# MMC register map
Vendor: Texas Instruments
Peripheral module from a debugger description file (folder am335x).
Registers are 32-bit, access per field, no defined reset value unless marked. A register's access mark holds for its fields unless they carry their own. Offsets are as the file gives them; lines under a group give offsets from that group; [hi:lo] are bit positions; {n}, {i} and the like mark numbered series; 'fields as' and 'values as' point back to an identical list; <NAME> marks a mode.

## Multimedia_Card (part 1 of 2)
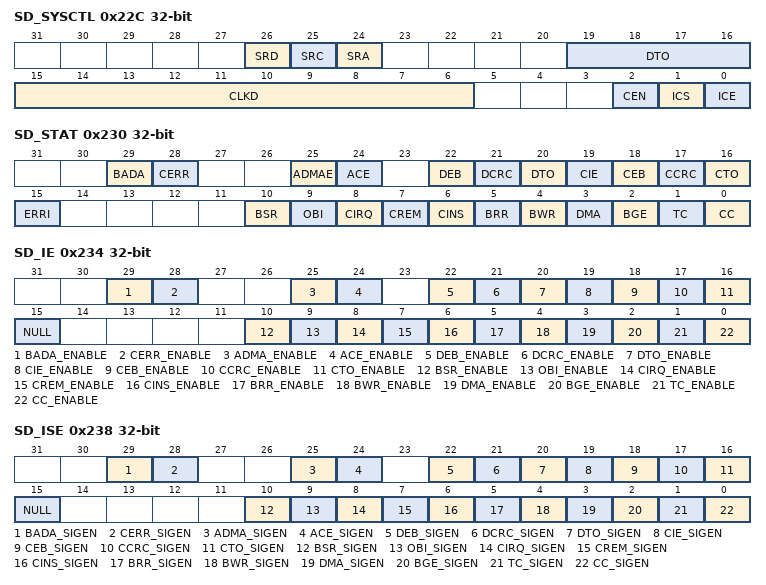
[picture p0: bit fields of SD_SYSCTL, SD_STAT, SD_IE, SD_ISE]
0x22C SD_SYSCTL — This register defines the system controls to set software resets, clock frequency management and data timeout. SD_SYSCTL[31:24] = Software resets. SD_SYSCTL[23:16] = Timeout control. SD_SYSCTL[15:0] = Clock control.
  [26] SRD rw — Software reset for mmc_dat line. This bit is set to 1 for reset and released to 0 when completed. Due to additional implementation logic, the reset does not immediately start when asserted. The proper procedure is: (a) Set to 1 to start reset, (b) Poll for 1 to identify start of reset, and (c) Poll for 0 to identify reset is complete. mmc_dat finite state machine in both clock domain are also reset. These registers are cleared by the SD_SYSCTL[26] SRD bit: SD_DATA. SD_PSTATEBRE, BWE, RTA, WTA, DLA and DATI. SD_HCTLSBGR and CR. SD_STATBRR, BWR, BGE and TC Interconnect and MMC buffer data management is reinitialized. Note: If a soft reset is issued when an interrupt is asserted, data may be lost.
  [25] SRC rw — Software reset for mmc_cmd line. This bit is set to 1 for reset and released to 0 when completed. Due to additional implementation logic, the reset does not immediately start when asserted. The proper procedure is: (a) Set to 1 to start reset, (b) Poll for 1 to identify start of reset, and (c) Poll for 0 to identify reset is complete. mmc_cmd finite state machine in both clock domain are also reset. These registers are cleared by the SD_SYSCTL[25] SRC bit: SD_PSTATECMDI. SD_STATCC Interconnect and MMC command status management is reinitialized. Note: If a soft reset is issued when an interrupt is asserted, data may be lost.
  [24] SRA rw — Software reset for all. This bit is set to 1 for reset , and released to 0 when completed. This reset affects the entire host controller except for the card detection circuit and capabilities registers.
  [19:16] DTO rw — Data timeout counter value and busy timeout. This value determines the interval by which mmc_dat lines timeouts are detected. The host driver needs to set this bit field based on: The maximum read access time (NAC) (Refer to the SD Specification Part1 Physical Layer). The data read access time values (TAAC and NSAC) in the card specific data register (CSD) of the card. The timeout clock base frequency (SD_CAPA[5:0] TCF bits). If the card does not respond within the specified number of cycles, a data timeout error occurs (SD_STAT[20] DTO bit). The SD_SYSCTL[19,16] DTO bit field is also used to check busy duration, to generate busy timeout for commands with busy response or for busy programming during a write command. Timeout on CRC status is generated if no CRC token is present after a block write.
  [15:6] CLKD rw — Clock frequency select. These bits define the ratio between a reference clock frequency (system dependant) and the output clock frequency on the mmc_clk pin of either the memory card (MMC, SD, or SDIO).
  [2] CEN rw — Clock enable. This bit controls if the clock is provided to the card or not.
  [1] ICS ro — Internal clock stable (status)This bit indicates either the internal clock is stable or not.
  [0] ICE rw — Internal clock enable. This register controls the internal clock activity. In very low power state, the internal clock is stopped. NoteThe activity of the debounce clock (used for wake-up events) and the interface clock (used for reads and writes to the module register map) are not affected by this register.
0x230 SD_STAT — The interrupt status regroups all the status of the module internal events that can generate an interrupt. SD_STAT[31:16] = Error Interrupt Status. SD_STAT[15:0] = Normal Interrupt Status. The error bits are located in the upper 16 bits of the SD_STAT register. All bits are cleared by writing a 1 to them. Additionally, bits 15 and 8 serve as special error bits. These cannot be cleared by writing a 1 to them. Bit 15 (ERRI) is automatically cleared when the error causing to ERRI to be set is handled. (that is, when bits 31:16 are cleared, bit 15 will be automatically cleared). Bit 8 (CIRQ) is cleared by writing a 0 to SD_IE[8] (masking the interrupt) and servicing the interrupt.
  [29] BADA rw — Bad access to data space. This bit is set automatically to indicate a bad access to buffer when not allowed: During a read access to the data register (SD_DATA) while buffer reads are not allowed (SD_PSTATE[11] BRE bit =0). During a write access to the data register (SD_DATA) while buffer writes are not allowed (SD_PSTATE[10] BWE bit=0).
  [28] CERR rw — Card error. This bit is set automatically when there is at least one error in a response of type R1, R1b, R6, R5 or R5b. Only bits referenced as type E (error) in status field in the response can set a card status error. An error bit in the response is flagged only if corresponding bit in card status response error SD_CSRE in set. There is no card error detection for autoCMD12 command. The host driver shall read SD_RSP76 register to detect error bits in the command response.
  [25] ADMAE rw — ADMA Error. This bit is set when the Host Controller detects errors during ADMA based data transfer. The state of the ADMA at an error occurrence is saved in the ADMA Error Status Register. In addition, the Host Controller generates this interrupt when it detects invalid descriptor data (Valid=0) at the ST_FDS state. ADMA Error State in the ADMA Error Status indicates that an error occurs in ST_FDS state. The Host Driver may find that Valid bit is not set at the error descriptor.
  [24] ACE rw — Auto CMD12 error. This bit is set automatically when one of the bits in Auto CMD12 Error status register has changed from 0 to 1.
  [22] DEB rw — Data End Bit error. This bit is set automatically when detecting a 0 at the end bit position of read data on mmc_dat line or at the end position of the CRC status in write mode.
  [21] DCRC rw — Data CRC Error. This bit is set automatically when there is a CRC16 error in the data phase response following a block read command or if there is a 3-bit CRC status different of a position "010" token during a block write command.
  [20] DTO rw — Data timeout error. This bit is set automatically according to the following conditions: Busy timeout for R1b, R5b response type. Busy timeout after write CRC status. Write CRC status timeout. Read data timeout.
  [19] CIE rw — Command index error. This bit is set automatically when response index differs from corresponding command index previously emitted. It depends on the enable bit (SD_CMD[20] CICE).
  [18] CEB rw — Command end bit error. This bit is set automatically when detecting a 0 at the end bit position of a command response.
  [17] CCRC rw — Command CRC error. This bit is set automatically when there is a CRC7 error in the command response depending on the enable bit (SD_CMD[19] CCCE).
  [16] CTO rw — Command timeout error. This bit is set automatically when no response is received within 64 clock cycles from the end bit of the command. For commands that reply within 5 clock cycles - the timeout is still detected at 64 clock cycles.
  [15] ERRI ro — Error interrupt. If any of the bits in the Error Interrupt Status register (SD_STAT[31:16]) are set, then this bit is set to 1. Therefore the host driver can efficiently test for an error by checking this bit first. Writes to this bit are ignored.
  [10] BSR rw — Boot Status Received Interrupt. This bit is set automatically when SD_CON[BOOT] is set 1 or 2 and a boot status is received on DAT[0] line. This interrupt is only useful for MMC card.
  [9] OBI ro — Out-of-band interrupt (This interrupt is only useful for MMC card). This bit is set automatically when SD_CON[14] OBIE bit is set and an out-of-band interrupt occurs on OBI pin. The interrupt detection depends on polarity controlled by SD_CON[13] OBIP bit. The out-of-band interrupt signal is a system specific feature for future use, this signal is not required for existing specification implementation.
  [8] CIRQ ro — Card interrupt. This bit is only used for SD and SDIO cards. In 1-bit mode, interrupt source is asynchronous (can be a source of asynchronous wake-up). In 4-bit mode, interrupt source is sampled during the interrupt cycle. In CE-ATA mode, interrupt source is detected when the card drives mmc_cmd line to zero during one cycle after data transmission end. All modes above are fully exclusive. The controller interrupt must be clear by setting SD_IE[8] CIRQ_ENABLE to 0, then the host driver must start the interrupt service with card (clearing card interrupt status) to remove card interrupt source. Otherwise the Controller interrupt will be reasserted as soon as SD_IE[8] CIRQ_ENABLE is set to 1. Writes to this bit are ignored.
  [7] CREM rw — Card Removal. This bit is set automatically when SD_PSTATE[CINS] changes from 1 to 0. A clear of this bit doesn't affect Card inserted present state (SD_PSTATE[CINS]).
  [6] CINS rw — Card Insertion. This bit is set automatically when SD_PSTATE[CINS] changes from 0 to 1. A clear of this bit doesn't affect Card inserted present state (SD_PSTATE[CINS]).
  [5] BRR rw — Buffer read ready. This bit is set automatically during a read operation to the card (see class 2 - block oriented read commands) when one block specified by the SD_BLK[10:0] BLEN bit field is completely written in the buffer. It indicates that the memory card has filled out the buffer and that the local host needs to empty the buffer by reading it. Note: If the DMA receive-mode is enabled, this bit is never set; instead a DMA receive request to the main DMA controller of the system is generated.
  [4] BWR rw — Buffer write ready. This bit is set automatically during a write operation to the card (see class 4 - block oriented write command) when the host can write a complete block as specified by SD_BLK[10:0] BLEN. It indicates that the memory card has emptied one block from the buffer and that the local host is able to write one block of data into the buffer. Note: If the DMA transmit mode is enabled, this bit is never set; instead, a DMA transmit request to the main DMA controller of the system is generated.
  [3] DMA rw — DMA Interrupt. This status is set when an interrupt is required in the ADMA instruction and after the data transfer completion.
  [2] BGE rw — Block gap event. When a stop at block gap is requested (SD_HCTL[16] SBGR bit), this bit is automatically set when transaction is stopped at the block gap during a read or write operation.
  [1] TC rw — Transfer completed. This bit is always set when a read/write transfer is completed or between two blocks when the transfer is stopped due to a stop at block gap request (SD_HCTL[16] SBGR bit).
  [0] CC rw — Command complete. This bit is set when a 1-to-0 transition occurs in the register command inhibit (SD_PSTATE[0] CMDI bit)
0x234 SD_IE — This register allows to enable/disable the module to set status bits, on an event-by-event basis. SD_IE[31:16] = Error Interrupt Status Enable. SD_IE[15:0] = Normal Interrupt Status Enable.
  [29] BADA_ENABLE rw — Bad access to data space interrupt enable
  [28] CERR_ENABLE rw — Card error interrupt enable
  [25] ADMA_ENABLE rw — ADMA error Interrupt Enable
  [24] ACE_ENABLE rw — Auto CMD12 error interrupt enable
  [22] DEB_ENABLE rw — Data end bit error interrupt enable
  [21] DCRC_ENABLE rw — Data CRC error interrupt enable
  [20] DTO_ENABLE rw — Data timeout error interrupt enable
  [19] CIE_ENABLE rw — Command index error interrupt enable
  [18] CEB_ENABLE rw — Command end bit error interrupt enable
  [17] CCRC_ENABLE rw — Command CRC error interrupt enable
  [16] CTO_ENABLE rw — Command timeout error interrupt enable
  [15] NULL ro — Fixed to 0. The host driver shall control error interrupts using the Error Interrupt Signal Enable register. Writes to this bit are ignored.
  [10] BSR_ENABLE rw — Boot Status Interrupt Enable A write to this register when SD_CON[BOOT] is cleared to 0 is ignored.
  [9] OBI_ENABLE rw — Out-of-band interrupt enable A write to this register when SD_CON[14] OBIE is cleared to 0 is ignored.
  [8] CIRQ_ENABLE rw — Card interrupt enable. A clear of this bit also clears the corresponding status bit. During 1-bit mode, if the interrupt routine does not remove the source of a card interrupt in the SDIO card, the status bit is reasserted when this bit is set to 1. This bit must be set to 1 when entering in smart idle mode to enable system to identity wake-up event and to allow controller to clear internal wake-up source.
  [7] CREM_ENABLE rw — Card Removal interrupt Enable This bit must be set to 1 when entering in smart idle mode to enable system to identity wake-up event and to allow controller to clear internal wake-up source.
  [6] CINS_ENABLE rw — Card Insertion interrupt Enable This bit must be set to 1 when entering in smart idle mode to enable system to identity wake-up event and to allow controller to clear internal wake-up source.
  [5] BRR_ENABLE rw — Buffer read ready interrupt enable
  [4] BWR_ENABLE rw — Buffer write ready interrupt enable
  [3] DMA_ENABLE rw — DMA interrupt enable
  [2] BGE_ENABLE rw — Block gap event interrupt enable
  [1] TC_ENABLE rw — Transfer completed interrupt enable
  [0] CC_ENABLE rw — Command completed interrupt enable
0x238 SD_ISE — This register allows you to enable/disable the module to set status bits, on an event-by-event basis. SD_ISE[31:16] = Error Interrupt Signal Enable. SD_ISE[15:0] = Normal Interrupt Signal Enable.
  [29] BADA_SIGEN rw — Bad access to data space interrupt enable
  [28] CERR_SIGEN rw — Card error interrupt signal status enable
  [25] ADMA_SIGEN rw — ADMA error signal status enable
  [24] ACE_SIGEN rw — Auto CMD12 error signal status enable
  [22] DEB_SIGEN rw — Data end bit error signal status enable
  [21] DCRC_SIGEN rw — Data CRC error signal status enable
  [20] DTO_SIGEN rw — Data timeout error signal status enable
  [19] CIE_SIGEN rw — Command index error signal status enable
  [18] CEB_SIGEN rw — Command end bit error signal status enable
  [17] CCRC_SIGEN rw — Command CRC error signal status enable
  [16] CTO_SIGEN rw — Command timeout error signal status enable
  [15] NULL ro — Fixed to 0. The host driver shall control error interrupts using the error interrupt signal enable register. Writes to this bit are ignored.
  [10] BSR_SIGEN rw — Boot Status signal status enable. A write to this register when SD_CON[BOOT] is cleared to 0 is ignored
  [9] OBI_SIGEN rw — Out-of-band interrupt signal status enable. A write to this register when SD_CON[14] OBIE is cleared to 0 is ignored.
  [8] CIRQ_SIGEN rw — Card interrupt signal status enable. A clear of this bit also clears the corresponding status bit. During 1-bit mode, if the interrupt routine does not remove the source of a card interrupt in the SDIO card, the status bit is reasserted when this bit is set to 1. This bit must be set to 1 when entering in smart idle mode to enable system to identity wake-up event and to allow controller to clear internal wake-up source.
  [7] CREM_SIGEN rw — Card Removal signal status enable This bit must be set to 1 when entering in smart idle mode to enable system to identity wake-up event and to allow controller to clear internal wake-up source.
  [6] CINS_SIGEN rw — Card Insertion signal status enable. This bit must be set to 1 when entering in smart idle mode to enable system to identity wake-up event and to allow controller to clear internal wake-up source.
  [5] BRR_SIGEN rw — Buffer read ready signal status enable
  [4] BWR_SIGEN rw — Buffer write ready signal status enable
  [3] DMA_SIGEN rw — DMA signal status enable
  [2] BGE_SIGEN rw — Block gap event signal status enable
  [1] TC_SIGEN rw — Transfer completed signal status enable
  [0] CC_SIGEN rw — Command completed signal status enable
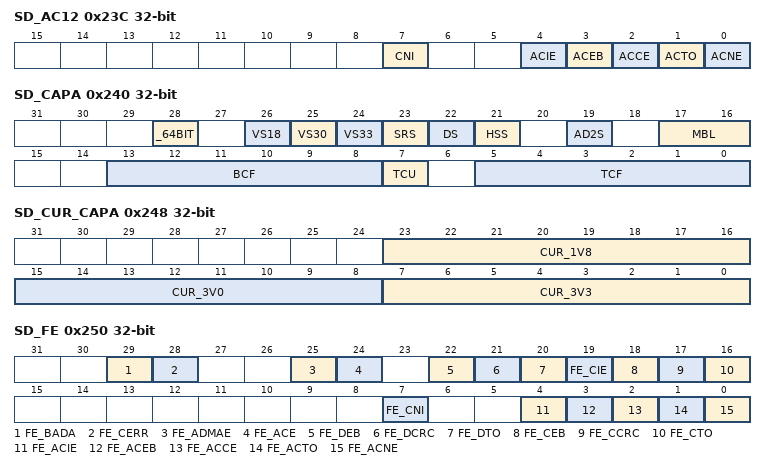
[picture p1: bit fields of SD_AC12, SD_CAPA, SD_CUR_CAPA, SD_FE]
0x23C SD_AC12 ro — The host driver may determine which of the errors cases related to Auto CMD12 has occurred by checking this SD_AC12 register when an auto CMD12 error interrupt occurs. This register is valid only when auto CMD12 is enabled (SD_CMD[2] ACEN bit) and auto CMD12Error (SD_STAT[24] ACE bit) is set to 1. These bits are automatically reset when starting a new adtc command with data.
  [7] CNI — Command not issue by auto CMD12 error. If this bit is set to 1, it means that pending command is not executed due to auto CMD12 error ACEB, ACCE, ACTO, or ACNE.
  [4] ACIE — Auto CMD12 index error. This bit is a set to 1 when response index differs from corresponding command auto CMD12 index previously emitted. This bit depends on the command index check enable (SD_CMD[20] CICE bit).
  [3] ACEB — Auto CMD12 end bit error. This bit is set to 1 when detecting a 0 at the end bit position of auto CMD12 command response.
  [2] ACCE — Auto CMD12 CRC error. This bit is automatically set to 1 when a CRC7 error is detected in the auto CMD12 command response depending on the enable in the SD_CMD[19] CCCE bit.
  [1] ACTO — Auto CMD12 timeout error. This bit is set to 1 if no response is received within 64 clock cycles from the end bit of the auto CMD12 command.
  [0] ACNE — Auto CMD12 not executed. This bit is set to 1 if multiple block data transfer command has started and if an error occurs in command before auto CMD12 starts.
0x240 SD_CAPA — This register lists the capabilities of the MMC/SD/SDIO host controller.
  [28] _64BIT rw — 64 Bit System Bus Support. Setting 1 to this bit indicates that the Host Controller supports 64-bit address descriptor mode and is connected to 64-bit address system bus.
  [26] VS18 rw — Voltage support 1.8 V. Initialization of this register (via a write access to this register) depends on the system capabilities. The host driver shall not modify this register after the initialization. This register is only reinitialized by a hard reset (via mmc_RESET signal).
  [25] VS30 rw — Voltage support 3.0V. Initialization of this register (via a write access to this register) depends on the system capabilities. The host driver shall not modify this register after the initialization. This register is only reinitialized by a hard reset (via mmc_RESET signal).
  [24] VS33 rw — Voltage support 3.3V. Initialization of this register (via a write access to this register) depends on the system capabilities. The host driver shall not modify this register after the initialization. This register is only reinitialized by a hard reset (via mmc_RESET signal).
  [23] SRS ro — Suspend/resume support (SDIO cards only). This bit indicates whether the host controller supports Suspend/Resume functionality.
  [22] DS ro — DMA support. This bit indicates that the Host controller is able to use DMA to transfer data between system memory and the Host controller directly.
  [21] HSS ro — High-speed support. This bit indicates that the host controller supports high speed operations and can supply an up-to-52 MHz clock to the card.
  [19] AD2S ro — This bit indicates whether the Host Controller is capable of using ADMA2. It depends on setting of generic parameter MADMA_EN.
  [17:16] MBL ro — Maximum block length. This value indicates the maximum block size that the host driver can read and write to the buffer in the host controller. The host controller supports 512 bytes and 1024 bytes block transfers.
  [13:8] BCF ro — Base clock frequency for clock provided to the card. ARRAY(0x1bfe1b0)
  [7] TCU ro — Timeout clock unit. This bit shows the unit of base clock frequency used to detect Data Timeout Error (SD_STAT[20] DTO bit).
  [5:0] TCF ro — Timeout clock frequency. The timeout clock frequency is used to detect Data Timeout Error (SD_STAT[20] DTO bit).
0x248 SD_CUR_CAPA — This register indicates the maximum current capability for each voltage. The value is meaningful if the voltage support is set in the capabilities register (SD_CAPA). Initialization of this register (via a write access to this register) depends on the system capabilities. The host driver shall not modify this register after the initialization. This register is only reinitialized by a hard reset (via mmc_RESET signal).
  [23:16] CUR_1V8 rw — Maximum current for 1.8 V
  [15:8] CUR_3V0 rw — Maximum current for 3.0 V
  [7:0] CUR_3V3 rw — Maximum current for 3.3 V
0x250 SD_FE — The Force Event register is not a physically implemented register. Rather, it is an address at which the Error Interrupt Status register can be written. The effect of a write to this address will be reflected in the Error Interrupt Status Register, if corresponding bit of the Error Interrupt Status Enable Register is set.
  [29] FE_BADA wo — Force Event Bad access to data space.
  [28] FE_CERR wo — Force Event Card error
  [25] FE_ADMAE wo — Force Event ADMA error
  [24] FE_ACE wo — Force Event Auto CMD12 error.
  [22] FE_DEB wo — Force Event Data End Bit error.
  [21] FE_DCRC wo — Force Event Data CRC error
  [20] FE_DTO wo — Force Event Data timeout error
  [19] FE_CIE wo — Force Event Command index error
  [18] FE_CEB wo — Force Event Command end bit error
  [17] FE_CCRC wo — Force Event Comemand CRC error
  [16] FE_CTO wo — Force Event Command Timeout error
  [7] FE_CNI wo — Force Event Command not issue by Auto CMD12 error
  [4] FE_ACIE wo — Force Event Auto CMD12 index error
  [3] FE_ACEB wo — Force Event Auto CMD12 end bit error
  [2] FE_ACCE wo — Force Event Auto CMD12 CRC error
  [1] FE_ACTO wo — Force Event Auto CMD12 timeout error
  [0] FE_ACNE wo — Force Event Auto CMD12 not executed.
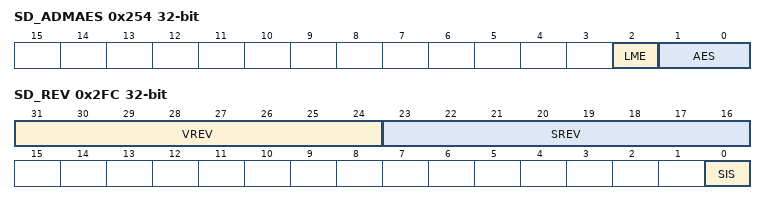
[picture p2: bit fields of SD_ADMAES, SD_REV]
0x254 SD_ADMAES — When an ADMA Error Interrupt has occurred, the ADMA Error States field in this register holds the ADMA state and the ADMA System Address Register holds the address around the error descriptor. For recovering the error, the Host Driver requires the ADMA state to identify the error descriptor address as follows: ST_STOP: Previous location set in the ADMA System Address register is the error descriptor address. ST_FDS: Current location set in the ADMA System Address register is the error descriptor address. ST_CADR: This sate is never set because do not generate ADMA error in this state. ST_TFR: Previous location set in the ADMA System Address register is the error descriptor address. In the case of a write operation, the Host Driver should use ACMD22 to get the number of written block rather than using this information, since unwritten data may exist in the Host Controller. The Host Controller generates the ADMA Error Interrupt when it detects invalid descriptor data (Valid = 0) at the ST_FDS state. In this case, ADMA Error State indicates that an error occurs at ST_FDS state. The Host Driver may find that the Valid bit is not set in the error descriptor.
  [2] LME wo — ADMA Length Mismatch Error: While Block Count Enable is being set, the total data length specified by the Descriptor table is different from that specified by the Block Count and Block Length. Total data length cannot be divided by the block length.
  [1:0] AES rw — ADMA Error State. This field indicates the state of ADMA when an error occurred during an ADMA data transfer. This field never indicates "10" because ADMA never stops in this state.
0x258 SD_ADMASAL rw — This register holds the byte address of the executing command of the Descriptor table. The 32-bit Address Descriptor uses the lower 32 bits of this register. At the start of ADMA, the Host Driver shall set the start address of the Descriptor table.
  [31:0] ADMA_A32B — The ADMA increments this register address, which points to the next line, whenever fetching a Descriptor line. When the ADMA Error Interrupt is generated, this register holds the valid Descriptor address depending on the ADMA state. The Host Driver shall program the Descriptor Table on a 32-bit boundary and set the 32-bit boundary address to this register. ADMA2 ignores the lower 2 bits of this register and assumes it to be 00b.
0x25C SD_ADMASAH rw
  [31:0] ADMA_A32B
0x2FC SD_REV ro — This register contains the hard coded RTL vendor revision number, the version number of SD specification compliancy and a slot status bit. SD_REV[31:16] = Host Controller Version. SD_REV[15:0] = Slot Interrupt Status.
  [31:24] VREV — Vendor Version Number. Bits [7:4] is the major revision, bits [3:0] is the minor revision. Examples: 10h for 1.0 21h for 2.1
  [23:16] SREV — Specification Version Number. This status indicates the Standard SD Host Controller Specification Version. The upper and lower 4-bits indicate the version.
  [0] SIS — Slot Interrupt Status. This status bit indicates the inverted state of interrupt signal for the module. By a power on reset or by setting a software reset for all (SD_SYSCTL[24] SRA), the interrupt signal shall be deasserted and this status shall read 0.
